# ATUC128D3 device description
Architecture: AVR32_UC3; Family: AVR UC3
Registers are 32-bit, read-write, reset 0x0 unless marked. A register's access mark holds for its fields unless they carry their own. Offsets are from the block's base; [hi:lo] are bit positions; {n}, {i} and the like mark numbered series; 'fields as' and 'values as' point back to an identical list.

## AW — aWire
Instances: AW 0xffff6800
0x00 CTRL — Control Register
  [1:0] MODE
    0=DISABLED; 1=RECEIVE; 2=TRANSMIT; 3=RECEIVESYNC
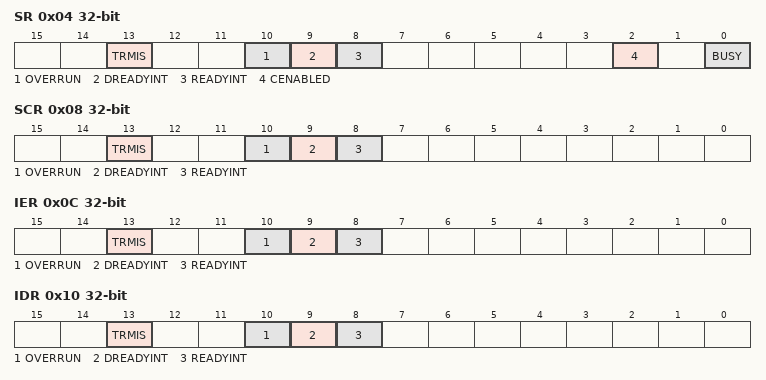
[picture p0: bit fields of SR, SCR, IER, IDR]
0x04 SR ro — Status Register
  [13] TRMIS — Transmit Mismatch
  [10] OVERRUN — Data Overrun
  [9] DREADYINT — Data Ready Interrupt
  [8] READYINT — Ready Interrupt
  [2] CENABLED — Clock Enabled
  [0] BUSY — Synchronizer Busy
0x08 SCR wo reset not defined — Status Clear Register
  [13] TRMIS — Transmit Mismatch
  [10] OVERRUN — Data Overrun
  [9] DREADYINT — Data Ready Interrupt
  [8] READYINT — Ready Interrupt
0x0C IER wo reset not defined — Interrupt Enable Register
  fields as SCR
0x10 IDR wo reset not defined — Interrupt Disable Register
  fields as SCR
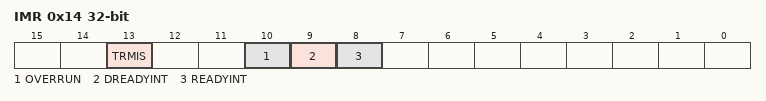
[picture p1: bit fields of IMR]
0x14 IMR ro — Interrupt Mask Register
  fields as SCR
0x18 RHR ro — Receive Holding Register
  [7:0] RXDATA — Received Data
0x1C THR — Transmit Holding Register
  [7:0] TXDATA — Transmit Data
0x20 BRR — Baud Rate Register
  [15:0] BR — Baud Rate
0x24 VERSION ro reset not defined
  [11:0] VERSION — Version Number
0x28 CLKR — Clock Request Register
  [0] CLKEN — Clock Enable
    0=DISABLE; 1=ENABLE

## EIC — External Interrupt Controller
Instances: EIC 0xffff2000
Parameters: EIC_EDGE_IRQ=0, EIC_FALLING_EDGE=0, EIC_FILTER_OFF=0, EIC_FILTER_ON=1, EIC_HIGH_LEVEL=1, EIC_LEVEL_IRQ=1, EIC_LOW_LEVEL=0, EIC_RISING_EDGE=1, EIC_SYNC=0, EIC_USE_ASYNC=1
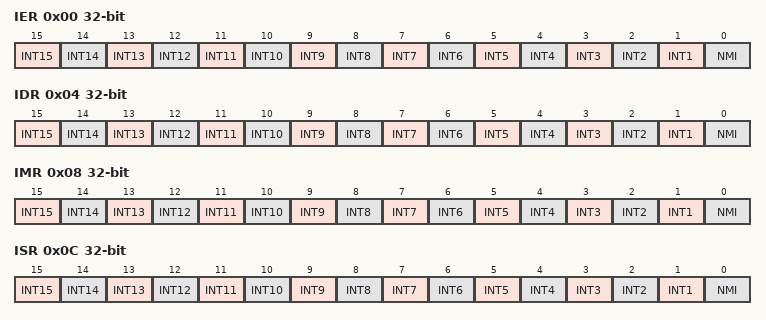
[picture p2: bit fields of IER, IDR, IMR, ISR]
0x00 IER wo — Interrupt Enable Register
  [n] INT{n} (n=1..15) — External Interrupt {n}
  [0] NMI — External Non Maskable CPU interrupt
0x04 IDR wo — Interrupt Disable Register
  fields as IER
0x08 IMR ro — Interrupt Mask Register
  fields as IER
0x0C ISR ro — Interrupt Status Register
  fields as IER
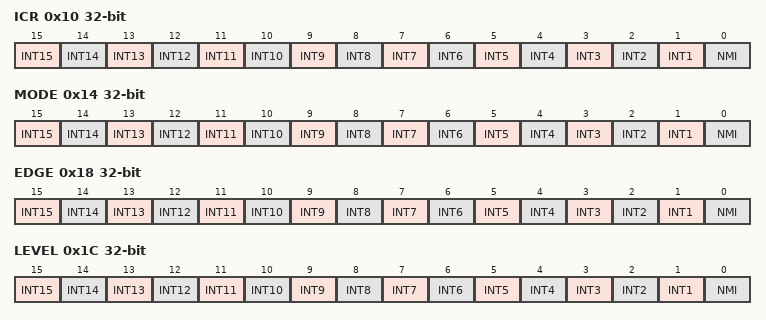
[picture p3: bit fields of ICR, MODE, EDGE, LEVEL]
0x10 ICR wo — Interrupt Clear Register
  fields as IER
0x14 MODE
  fields as IER
0x18 EDGE
  fields as IER
0x1C LEVEL
  fields as IER
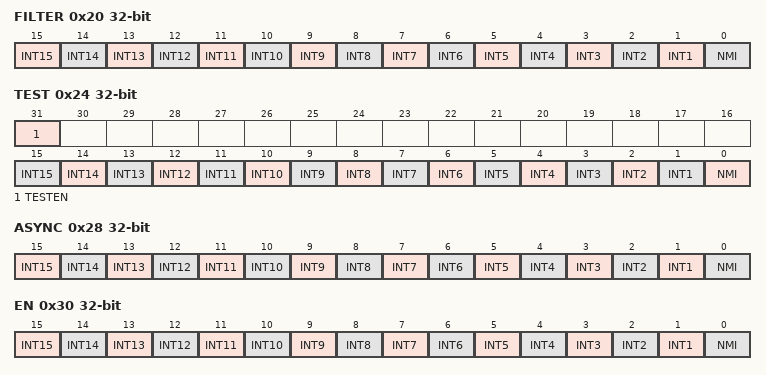
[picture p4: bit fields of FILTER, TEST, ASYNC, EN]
0x20 FILTER
  fields as IER
0x24 TEST
  [31] TESTEN — Test Enable
  [n] INT{n} (n=1..15) — External Interrupt {n}
  [0] NMI — External Non Maskable CPU interrupt
0x28 ASYNC — Asynchronous Register
  fields as IER
0x30 EN wo — Enable Register
  fields as IER
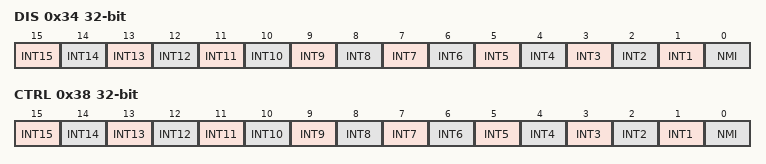
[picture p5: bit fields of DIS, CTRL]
0x34 DIS wo — Disable Register
  fields as IER
0x38 CTRL ro — Control Register
  fields as IER
0x3FC VERSION ro reset 0x302
  [11:0] VERSION — Version bits

## FLASHCDW — Flash Controller
Instances: FLASHCDW 0xfffe1400
Parameters: GPF_NUM=32
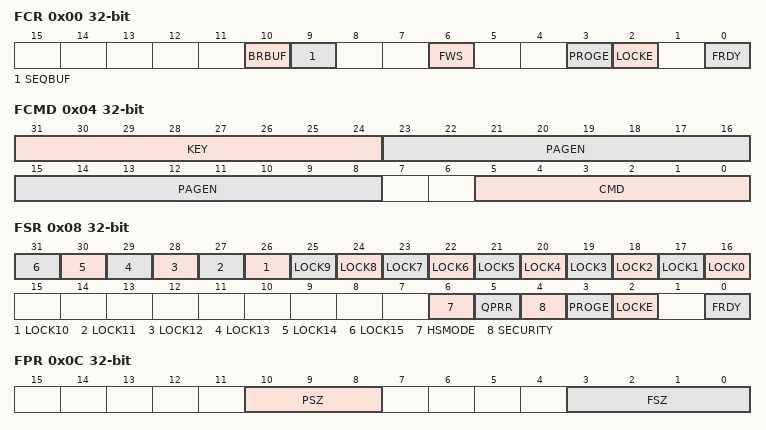
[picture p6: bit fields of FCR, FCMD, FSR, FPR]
0x00 FCR — Flash Controller Control Register
  [10] BRBUF — Branch Target Instruction Buffer Enable
  [9] SEQBUF — Sequential Instruction Fetch Buffer Enable
  [6] FWS — Flash Wait State
  [3] PROGE — Programming Error Interrupt Enable
  [2] LOCKE — Lock Error Interrupt Enable
  [0] FRDY — Flash Ready Interrupt Enable
0x04 FCMD — Flash Controller Command Register
  [31:24] KEY — Write protection key
    165=KEY
  [23:8] PAGEN — Page number
  [5:0] CMD — Command
    0=NOP; 1=WP; 2=EP; 3=CPB; 4=LP; 5=UP; 6=EA; 7=WGPB; 8=EGPB; 9=SSB; 10=PGPFB; 11=EAGPF; 12=QPR; 13=WUP; 14=EUP; 15=QPRUP; 16=HSEN; 17=HSDIS
0x08 FSR reset not defined — Flash Controller Status Register
  [n+16] LOCK{n} (n=0..15) — Lock Region {n} Lock Status
  [6] HSMODE — High Speed Mode
  [5] QPRR — Quick Page Read Result
  [4] SECURITY — Security Bit Status
  [3] PROGE — Programming Error Status
  [2] LOCKE — Lock Error Status
  [0] FRDY — Flash Ready Status
0x0C FPR ro reset not defined — Flash Controller Parameter Register
  [10:8] PSZ — Page Size
  [3:0] FSZ — Flash Size
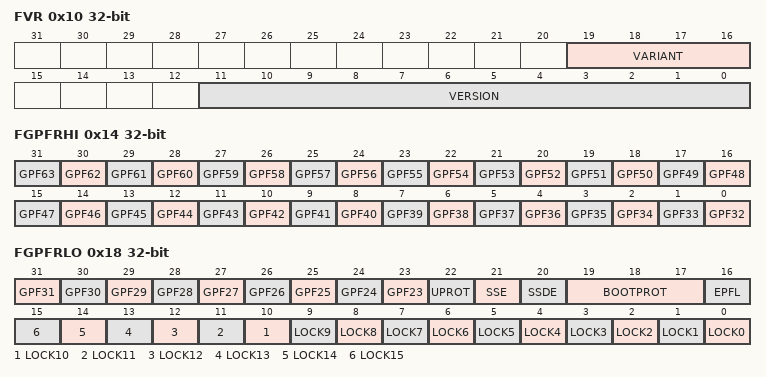
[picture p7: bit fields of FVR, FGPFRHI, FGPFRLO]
0x10 FVR ro reset not defined — Flash Controller Version Register
  [19:16] VARIANT — Variant Number
  [11:0] VERSION — Version Number
0x14 FGPFRHI ro reset not defined — Flash Controller General Purpose Fuse Register High
  [n-32] GPF{n} (n=32..63) — General Purpose Fuse {n}
0x18 FGPFRLO ro reset not defined — Flash Controller General Purpose Fuse Register Low
  [n] GPF{n} (n=23..31) — General Purpose Fuse {n}
  [22] UPROT — Jtag user protection
  [21] SSE — Secure state enable
  [20] SSDE — Secure state debug enable
  [19:17] BOOTPROT — Boot Section Protection size
  [16] EPFL — External Privileged mode fetch lock
  [n] LOCK{n} (n=0..15) — Lock Bit {n}
